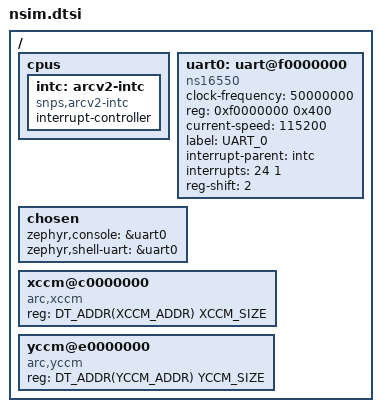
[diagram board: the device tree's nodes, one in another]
/*
 * Copyright (c) 2018, 2019, Synopsys, Inc. All rights reserved.
 *
 * SPDX-License-Identifier: Apache-2.0
 */

/dts-v1/;
#include <mem.h>
#include "skeleton.dtsi"


/ {
	cpus {
		#address-cells = <1>;
		#size-cells = <0>;

		intc: arcv2-intc {
			compatible = "snps,arcv2-intc";
			interrupt-controller;
			#interrupt-cells = <2>;
		};
	};

	uart0: uart@f0000000 {
		compatible = "ns16550";
		clock-frequency = <50000000>;
		reg = <0xf0000000 0x400>;
		current-speed = <115200>;
		label = "UART_0";
		interrupt-parent = <&intc>;
		interrupts = <24 1>;
		reg-shift = <2>;
	};

	chosen {
		zephyr,console = &uart0;
		zephyr,shell-uart = &uart0;
	};
	
	xccm@c0000000 {
		compatible = "arc,xccm";
		reg = <DT_ADDR(XCCM_ADDR) XCCM_SIZE>;
	};

	yccm@e0000000 {
		compatible = "arc,yccm";
		reg = <DT_ADDR(YCCM_ADDR) YCCM_SIZE>;
	};
};
